# nrf5002 register map
Vendor: Nordic Semiconductor; Series: nRF50; File version: 1
CPU: CM0 r0p4, little endian, no MPU, no FPU, 2 interrupt priority bits, 32 interrupts
Registers are 32-bit, read-write, reset 0x0 unless marked. A register's access mark holds for its fields unless they carry their own. Offsets are from the block's base; [hi:lo] are bit positions; lines under a group give offsets from that group; 'fields as' and 'values as' point back to an identical list.

## RESET — Reset control
Base 0x40000000; alternate view of CLOCK
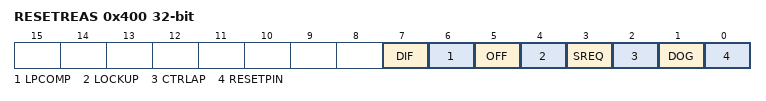
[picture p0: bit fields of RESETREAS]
0x400 RESETREAS — Reset reason
  [all] fields
    0=NotDetected; 1=Detected
  [7] DIF — Reset due to wakeup from System OFF mode when wakeup is triggered by entering the debug interface mode
  [6] LPCOMP — Reset due to wakeup from System OFF mode when wakeup is triggered by ANADETECT signal from LPCOMP
  [5] OFF — Reset due to wakeup from System OFF mode when wakeup is triggered by DETECT signal from GPIO
  [4] LOCKUP — Reset from CPU lockup detected
  [3] SREQ — Reset from soft reset detected
  [2] CTRLAP — Reset from CTRL-AP detected
  [1] DOG — Reset from watchdog timer detected
  [0] RESETPIN — Reset from pin reset detected

## AMLI — AHB Multi-Layer Interface
Base 0x41000000; alternate view of PCGCSLAVE_AMLI
0x600 RAMPRI group — RAM configurable priority configuration structure
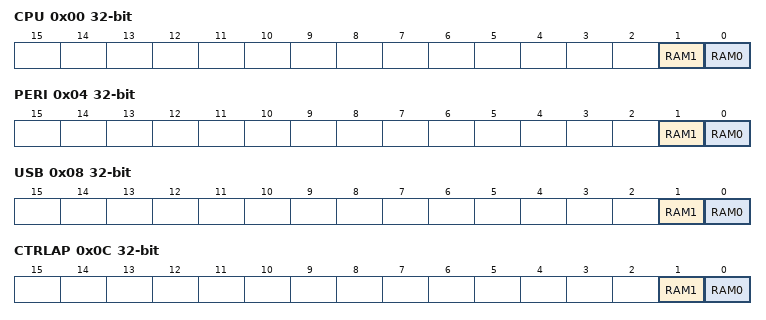
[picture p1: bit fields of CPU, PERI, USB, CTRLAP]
  0x00 CPU — AHB bus master priority register for CPU
    [1] RAM1 — Priority register for RAM AHB slave 1
      0=Pri0 (Priority 0); 1=Pri1 (Priority 1)
    [0] RAM0 — Priority register for RAM AHB slave 0
      0=Pri0 (Priority 0); 1=Pri1 (Priority 1)
  0x04 PERI — AHB bus master priority register for periperals
    fields as RAMPRI.CPU
  0x08 USB — AHB bus master priority register for USB
    fields as RAMPRI.CPU
  0x0C CTRLAP — AHB bus master priority register for CTRL-AP
    fields as RAMPRI.CPU

## OSCILLATORS — Oscillator control
Base 0x40001000
0x584 ATECLOCK — Analog test bus control for clock modules
0x600 BYPASSHFXOSC — Enable or disable bypass of HFCLK crystal oscillator with external clock source
  [0] BYPASS
    0=Disabled (Disable (use with crystal or low-swing external source)); 1=Enabled (Enable (use with rail-to-rail external source))
0x680 PLL64M group — Unspecified
  0x00 BYPASS — PLL64M bypass control
    [0] BYPASS — Enable or disable bypass of PLL64M by an external clock source
      0=Disabled; 1=Enabled
  0x04 MUTE — Mute the PLL64M
    [0] MUTE — Mute output clock
      0=Disabled; 1=Enabled
  0x08 PROGCHPUMP — Program charge pump current
    [0] PROGCHPUMP — Program charge pump current (only used for debugging)
  0x0C VCOTRIM — VCO trim value for the 64 MHz PLL
    [5:0] VCOTRIM
  0x10 VCOTRIMOVERRIDE — Control overriding of the VCO trim values
    [0] VCOTRIMOVERRIDE — VCO trim value for the 64 MHz PLL
      0=Disabled (VCO trim values are coming from FICR); 1=Enabled (VCO trim values are coming from the VCOTRIM register)

## RNG — Random Number Generator
Base 0x40003000
0x00 TASKS_START wo — Task starting the random number generator
  [0] TASKS_START
    1=Trigger task
0x04 TASKS_STOP wo — Task stopping the random number generator
  [0] TASKS_STOP
    1=Trigger task
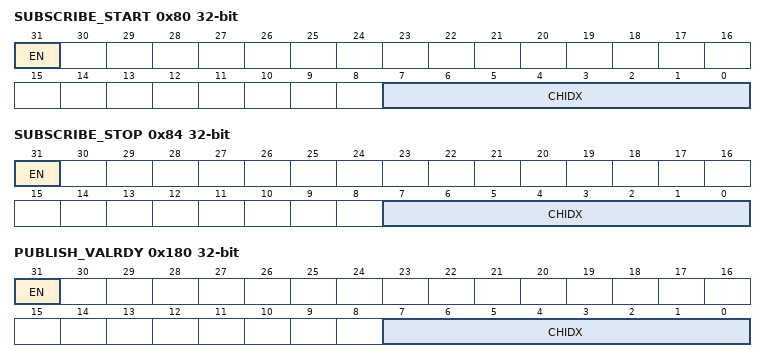
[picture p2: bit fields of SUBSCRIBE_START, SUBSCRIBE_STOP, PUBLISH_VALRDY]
0x80 SUBSCRIBE_START — Subscribe configuration for task START
  [31] EN
    0=Disabled (Disable subscription); 1=Enabled (Enable subscription)
  [7:0] CHIDX — DPPI channel that task START will subscribe to
0x84 SUBSCRIBE_STOP — Subscribe configuration for task STOP
  [31] EN
    values as SUBSCRIBE_START.EN
  [7:0] CHIDX — DPPI channel that task STOP will subscribe to
0x100 EVENTS_VALRDY — Event being generated for every new random number written to the VALUE register
  [0] EVENTS_VALRDY
    0=NotGenerated (Event not generated); 1=Generated (Event generated)
0x180 PUBLISH_VALRDY — Publish configuration for event VALRDY
  [31] EN
    0=Disabled (Disable publishing); 1=Enabled (Enable publishing)
  [7:0] CHIDX — DPPI channel that event VALRDY will publish to
0x200 SHORTS — Shortcuts between local events and tasks
  [0] VALRDY_STOP — Shortcut between event VALRDY and task STOP
    0=Disabled (Disable shortcut); 1=Enabled (Enable shortcut)
0x300 INTEN — Enable or disable interrupt
  [0] VALRDY — Enable or disable interrupt for event VALRDY
    0=Disabled; 1=Enabled
0x304 INTENSET — Enable interrupt
  [0] VALRDY — Write '1' to enable interrupt for event VALRDY
    on read: 0=Disabled (Read: Disabled); 1=Enabled (Read: Enabled) | on write: 1=Set (Enable)
0x308 INTENCLR — Disable interrupt
  [0] VALRDY — Write '1' to disable interrupt for event VALRDY
    on read: 0=Disabled (Read: Disabled); 1=Enabled (Read: Enabled) | on write: 1=Clear (Disable)
0x504 CONFIG — Configuration register
  [0] DERCEN — Bias correction
    0=Disabled; 1=Enabled
0x508 VALUE ro — Output random number
  [7:0] VALUE — Generated random number
0xFFC POWER reset 0x1 — Peripheral power control
  [0] POWER — Peripheral power control. The peripheral and its registers will be reset to its initial state by switching the peripheral off and then back on again.
    0=Disabled (Peripheral is powered off); 1=Enabled (Peripheral is powered on)
